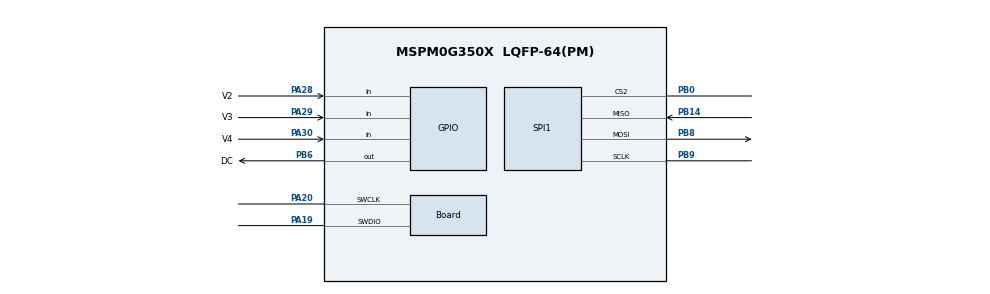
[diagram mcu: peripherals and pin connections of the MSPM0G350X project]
/**
 * @cliArgs --device "MSPM0G350X" --package "LQFP-64(PM)" --part "Default" --product "mspm0_sdk@1.20.01.06"
 * @versions {"tool":"1.18.1+3343"}
 */

/**
 * Import the modules used in this configuration.
 */
const ADC12         = scripting.addModule("/ti/driverlib/ADC12", {}, false);
const ADC121        = ADC12.addInstance();
const ADC122        = ADC12.addInstance();
const Board         = scripting.addModule("/ti/driverlib/Board");
const GPIO          = scripting.addModule("/ti/driverlib/GPIO", {}, false);
const GPIO1         = GPIO.addInstance();
const GPIO2         = GPIO.addInstance();
const SPI           = scripting.addModule("/ti/driverlib/SPI", {}, false);
const SPI1          = SPI.addInstance();
const SYSCTL        = scripting.addModule("/ti/driverlib/SYSCTL");
const TIMER         = scripting.addModule("/ti/driverlib/TIMER", {}, false);
const TIMER1        = TIMER.addInstance();
const UART          = scripting.addModule("/ti/driverlib/UART", {}, false);
const UART1         = UART.addInstance();
const UART2         = UART.addInstance();
const VREF          = scripting.addModule("/ti/driverlib/VREF");
const ProjectConfig = scripting.addModule("/ti/project_config/ProjectConfig");

/**
 * Write custom configuration values to the imported modules.
 */
const gate7  = system.clockTree["MFCLKGATE"];
gate7.enable = true;

const gate8  = system.clockTree["MFPCLKGATE"];
gate8.enable = true;

ADC121.$name                      = "ADC12_0";
ADC121.repeatMode                 = true;
ADC121.enabledInterrupts          = ["DL_ADC12_INTERRUPT_MEM0_RESULT_LOADED"];
ADC121.adcMem0vref                = "VREF";
ADC121.sampClkDiv                 = "DL_ADC12_CLOCK_DIVIDE_8";
ADC121.sampleTime0                = "195.3125us";
ADC121.peripheral.$assign         = "ADC0";
ADC121.peripheral.adcPin0.$assign = "PA27";
ADC121.adcPin0Config.$name        = "ti_driverlib_gpio_GPIOPinGeneric8";

ADC122.$name                      = "ADC12_1";
ADC122.startAdd                   = 1;
ADC122.repeatMode                 = true;
ADC122.adcMem1vref                = "VREF";
ADC122.adcMem1chansel             = "DL_ADC12_INPUT_CHAN_1";
ADC122.sampClkDiv                 = "DL_ADC12_CLOCK_DIVIDE_8";
ADC122.enabledInterrupts          = ["DL_ADC12_INTERRUPT_MEM1_RESULT_LOADED"];
ADC122.sampleTime0                = "195.3125us";
ADC122.peripheral.adcPin1.$assign = "PA16";
ADC122.adcPin1Config.$name        = "ti_driverlib_gpio_GPIOPinGeneric10";

Board.peripheral.$assign          = "DEBUGSS";
Board.peripheral.swclkPin.$assign = "PA20";
Board.peripheral.swdioPin.$assign = "PA19";

GPIO1.$name                              = "KEY";
GPIO1.port                               = "PORTA";
GPIO1.associatedPins.create(8);
GPIO1.associatedPins[0].$name            = "H1";
GPIO1.associatedPins[0].assignedPin      = "0";
GPIO1.associatedPins[0].internalResistor = "PULL_UP";
GPIO1.associatedPins[1].$name            = "H2";
GPIO1.associatedPins[1].assignedPin      = "1";
GPIO1.associatedPins[1].internalResistor = "PULL_UP";
GPIO1.associatedPins[2].$name            = "H3";
GPIO1.associatedPins[2].assignedPin      = "12";
GPIO1.associatedPins[3].$name            = "H4";
GPIO1.associatedPins[3].assignedPin      = "17";
GPIO1.associatedPins[4].$name            = "V1";
GPIO1.associatedPins[4].direction        = "INPUT";
GPIO1.associatedPins[4].internalResistor = "PULL_UP";
GPIO1.associatedPins[5].$name            = "V2";
GPIO1.associatedPins[5].direction        = "INPUT";
GPIO1.associatedPins[5].assignedPin      = "28";
GPIO1.associatedPins[5].internalResistor = "PULL_UP";
GPIO1.associatedPins[5].pin.$assign      = "PA28";
GPIO1.associatedPins[6].$name            = "V3";
GPIO1.associatedPins[6].direction        = "INPUT";
GPIO1.associatedPins[6].assignedPin      = "29";
GPIO1.associatedPins[6].internalResistor = "PULL_UP";
GPIO1.associatedPins[6].pin.$assign      = "PA29";
GPIO1.associatedPins[7].$name            = "V4";
GPIO1.associatedPins[7].direction        = "INPUT";
GPIO1.associatedPins[7].assignedPin      = "30";
GPIO1.associatedPins[7].internalResistor = "PULL_UP";
GPIO1.associatedPins[7].pin.$assign      = "PA30";

GPIO2.$name                         = "OLED";
GPIO2.associatedPins[0].$name       = "DC";
GPIO2.associatedPins[0].assignedPin = "6";
GPIO2.associatedPins[0].pin.$assign = "PB6";

SPI1.$name                      = "SPI_0";
SPI1.chipSelect                 = ["2"];
SPI1.peripheral.$assign         = "SPI1";
SPI1.peripheral.sclkPin.$assign = "PB9";
SPI1.peripheral.mosiPin.$assign = "PB8";
SPI1.peripheral.misoPin.$assign = "PB14";
SPI1.peripheral.cs2Pin.$assign  = "PB0";
SPI1.sclkPinConfig.$name        = "ti_driverlib_gpio_GPIOPinGeneric0";
SPI1.mosiPinConfig.$name        = "ti_driverlib_gpio_GPIOPinGeneric1";
SPI1.misoPinConfig.$name        = "ti_driverlib_gpio_GPIOPinGeneric2";
SPI1.cs2PinConfig.$name         = "ti_driverlib_gpio_GPIOPinGeneric4";

SYSCTL.MFCLKEn     = true;
SYSCTL.MFPCLKEn    = true;
SYSCTL.clockTreeEn = true;

TIMER1.$name            = "TIMER_0";
TIMER1.timerMode        = "PERIODIC";
TIMER1.timerStartTimer  = true;
TIMER1.timerClkSrc      = "MFCLK";
TIMER1.timerClkDiv      = 8;
TIMER1.timerClkPrescale = 8;
TIMER1.timerPeriod      = "1000 ms";
TIMER1.interrupts       = ["ZERO"];

UART1.$name              = "UART_0";
UART1.targetBaudRate     = 115200;
UART1.enabledInterrupts  = ["RX"];
UART1.peripheral.$assign = "UART0";
UART1.txPinConfig.$name  = "ti_driverlib_gpio_GPIOPinGeneric3";
UART1.rxPinConfig.$name  = "ti_driverlib_gpio_GPIOPinGeneric5";

UART2.$name              = "UART_1";
UART2.targetBaudRate     = 115200;
UART2.enabledInterrupts  = ["RX"];
UART2.peripheral.$assign = "UART2";
UART2.txPinConfig.$name  = "ti_driverlib_gpio_GPIOPinGeneric6";
UART2.rxPinConfig.$name  = "ti_driverlib_gpio_GPIOPinGeneric7";

VREF.basicIntVolt           = "DL_VREF_BUFCONFIG_OUTPUT_2_5V";
VREF.checkVREFReady         = true;
VREF.basicMode              = "DL_VREF_ENABLE_DISABLE";
VREF.basicExtVolt           = 3.3;
VREF.vrefPosPinConfig.$name = "ti_driverlib_gpio_GPIOPinGeneric9";

ProjectConfig.deviceSpin = "MSPM0G3507";

/**
 * Pinmux solution for unlocked pins/peripherals. This ensures that minor changes to the automatic solver in a future
 * version of the tool will not impact the pinmux you originally saw.  These lines can be completely deleted in order to
 * re-solve from scratch.
 */
ADC122.peripheral.$suggestSolution           = "ADC1";
GPIO1.associatedPins[0].pin.$suggestSolution = "PA0";
GPIO1.associatedPins[1].pin.$suggestSolution = "PA1";
GPIO1.associatedPins[2].pin.$suggestSolution = "PA12";
GPIO1.associatedPins[3].pin.$suggestSolution = "PA17";
GPIO1.associatedPins[4].pin.$suggestSolution = "PA13";
TIMER1.peripheral.$suggestSolution           = "TIMA0";
UART1.peripheral.rxPin.$suggestSolution      = "PA11";
UART1.peripheral.txPin.$suggestSolution      = "PA10";
UART2.peripheral.rxPin.$suggestSolution      = "PA22";
UART2.peripheral.txPin.$suggestSolution      = "PA21";
VREF.peripheral.$suggestSolution             = "VREF";
VREF.peripheral.vrefPosPin.$suggestSolution  = "PA23";
